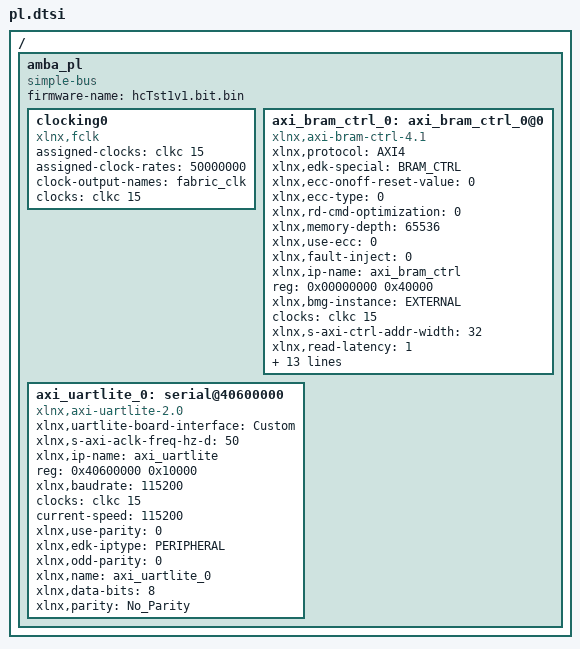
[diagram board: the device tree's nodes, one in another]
/ {
	amba_pl: amba_pl {
		ranges;
		compatible = "simple-bus";
		#address-cells = <1>;
		#size-cells = <1>;
		firmware-name = "hcTst1v1.bit.bin";
		clocking0: clocking0 {
			compatible = "xlnx,fclk";
			assigned-clocks = <&clkc 15>;
			assigned-clock-rates = <50000000>;
			#clock-cells = <0>;
			clock-output-names = "fabric_clk";
			clocks = <&clkc 15>;
		};
		axi_bram_ctrl_0: axi_bram_ctrl_0@0 {
			xlnx,protocol = "AXI4";
			xlnx,edk-special = "BRAM_CTRL";
			compatible = "xlnx,axi-bram-ctrl-4.1" , "xlnx,axi-bram-ctrl";
			xlnx,ecc-onoff-reset-value = <0>;
			xlnx,ecc-type = <0>;
			xlnx,rd-cmd-optimization = <0>;
			xlnx,memory-depth = <65536>;
			xlnx,use-ecc = <0>;
			xlnx,fault-inject = <0>;
			xlnx,ip-name = "axi_bram_ctrl";
			reg = <0x00000000 0x40000>;
			xlnx,bmg-instance = "EXTERNAL";
			clocks = <&clkc 15>;
			xlnx,s-axi-ctrl-addr-width = <32>;
			xlnx,read-latency = <1>;
			xlnx,id-width = <0>;
			xlnx,s-axi-supports-narrow-burst = <0>;
			xlnx,supports-narrow-burst = <0>;
			xlnx,single-port-bram = <1>;
			xlnx,ecc = <0>;
			xlnx,edk-iptype = "PERIPHERAL";
			status = "okay";
			clock-names = "s_axi_aclk";
			xlnx,data-width = <32>;
			xlnx,bram-addr-width = <16>;
			xlnx,bram-inst-mode = "EXTERNAL";
			xlnx,s-axi-ctrl-data-width = <32>;
			xlnx,mem-depth = <65536>;
			xlnx,s-axi-id-width = <1>;
			xlnx,name = "axi_bram_ctrl_0";
		};
		axi_uartlite_0: serial@40600000 {
			compatible = "xlnx,axi-uartlite-2.0" , "xlnx,xps-uartlite-1.00.a";
			xlnx,uartlite-board-interface = "Custom";
			xlnx,s-axi-aclk-freq-hz-d = <50>;
			xlnx,ip-name = "axi_uartlite";
			reg = <0x40600000 0x10000>;
			xlnx,baudrate = <115200>;
			clocks = <&clkc 15>;
			current-speed = <115200>;
			xlnx,use-parity = <0>;
			xlnx,edk-iptype = "PERIPHERAL";
			xlnx,odd-parity = <0>;
			status = "okay";
			clock-names = "s_axi_aclk";
			xlnx,name = "axi_uartlite_0";
			xlnx,data-bits = <8>;
			xlnx,parity = "No_Parity";
		};
	};
};
